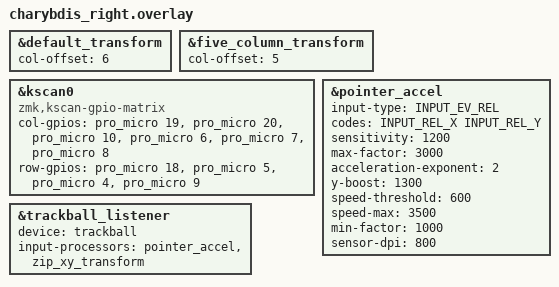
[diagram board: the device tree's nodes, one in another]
#include "charybdis.dtsi"
#include "charybdis_pmw3610.dtsi"

#include <input/processors.dtsi>
#include <behaviors/input_gestures_accel.dtsi>

// The matrix transform is 6 columns over because the left half is 6 columns wide.
&default_transform {
	col-offset = <6>;
};

&five_column_transform {
	col-offset = <5>;
};

// KSCAN matrix
&kscan0 {
	compatible = "zmk,kscan-gpio-matrix";
	
	col-gpios
		= <&pro_micro 19 (GPIO_ACTIVE_HIGH | GPIO_PULL_DOWN)>
		, <&pro_micro 20 (GPIO_ACTIVE_HIGH | GPIO_PULL_DOWN)>
		, <&pro_micro 10 (GPIO_ACTIVE_HIGH | GPIO_PULL_DOWN)>
		, <&pro_micro 6 (GPIO_ACTIVE_HIGH | GPIO_PULL_DOWN)>
		, <&pro_micro 7 (GPIO_ACTIVE_HIGH | GPIO_PULL_DOWN)>
		, <&pro_micro 8 (GPIO_ACTIVE_HIGH | GPIO_PULL_DOWN)>
		;

	row-gpios
		= <&pro_micro 18 GPIO_ACTIVE_HIGH>
		, <&pro_micro 5 GPIO_ACTIVE_HIGH>
		, <&pro_micro 4 GPIO_ACTIVE_HIGH>
		, <&pro_micro 9 GPIO_ACTIVE_HIGH>
		;
};

&pointer_accel {
    input-type = <INPUT_EV_REL>;
    codes = <INPUT_REL_X INPUT_REL_Y>;
    sensitivity = <1200>;         // 1.2x base sensitivity
    max-factor = <3000>;          // 3.0x maximum acceleration
    acceleration-exponent = <2>;  // Advanced exponential curve (1-5)
    y-boost = <1300>;             // 1.3x Y-axis boost for widescreen
    speed-threshold = <600>;      // Start acceleration at 600 counts/sec
    speed-max = <3500>;           // Max acceleration at 3500 counts/sec
    min-factor = <1000>;          // 1.0x minimum (no deceleration)
    sensor-dpi = <800>;           // 800 DPI sensor (optional, defaults to 800)
};

/* enable the listener on central */
&trackball_listener {
    status = "okay";
    device = <&trackball>;
    input-processors = <
        &pointer_accel      // Acceleration processor
        &zip_xy_transform
    >;
};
